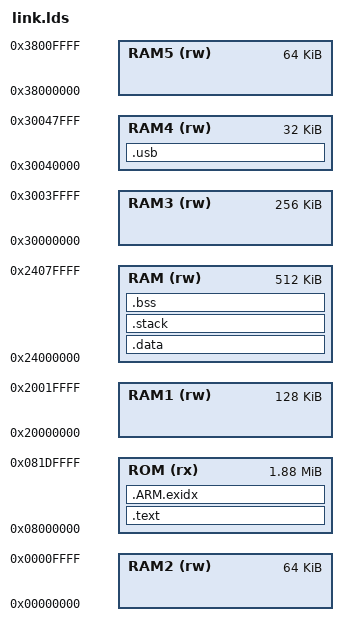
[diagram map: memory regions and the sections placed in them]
/*
 * linker script for STM32F4xx with GNU ld
 * bernard.xiong 2009-10-14
 */

/* Program Entry, set to mark it as "used" and avoid gc */
MEMORY
{
ROM  (rx) : ORIGIN =0x08000000,LENGTH =1920k
RAM  (rw) : ORIGIN =0x24000000,LENGTH =512k
RAM1 (rw) : ORIGIN =0x20000000,LENGTH =128k
RAM2 (rw) : ORIGIN =0x00000000,LENGTH =64K
RAM3 (rw) : ORIGIN =0x30000000,LENGTH =256k
RAM4 (rw) : ORIGIN =0x30040000,LENGTH =32k
RAM5 (rw) : ORIGIN =0x38000000,LENGTH =64k
}
ENTRY(Reset_Handler)
_system_stack_size = 0x200;

SECTIONS
{
    .text :
    {
        . = ALIGN(4);
        _stext = .;
        KEEP(*(.isr_vector))            /* Startup code */

        . = ALIGN(4);
        *(.text)                        /* remaining code */
        *(.text.*)                      /* remaining code */
        *(.rodata)                      /* read-only data (constants) */
        *(.rodata*)
        *(.glue_7)
        *(.glue_7t)
        *(.gnu.linkonce.t*)
        
        /* section information for finsh shell */
        . = ALIGN(4);
        __fsymtab_start = .;
        KEEP(*(FSymTab))
        __fsymtab_end = .;
        
        /* section information for usbh class */
        . = ALIGN(4);
        __usbh_class_info_start__ = .;
        KEEP(*(.usbh_class_info))
        __usbh_class_info_end__ = .;
        
        . = ALIGN(4);
        __vsymtab_start = .;
        KEEP(*(VSymTab))
        __vsymtab_end = .;
        
        /* section information for utest */
        . = ALIGN(4);
        __rt_utest_tc_tab_start = .;
        KEEP(*(UtestTcTab))
        __rt_utest_tc_tab_end = .;

        /* section information for initial. */
        . = ALIGN(4);
        __rt_init_start = .;
        KEEP(*(SORT(.rti_fn*)))
        __rt_init_end = .;
        
        /* section information for modules */
        . = ALIGN(4);
        __rtmsymtab_start = .;
        KEEP(*(RTMSymTab))
        __rtmsymtab_end = .;

        . = ALIGN(4);
        PROVIDE(__ctors_start__ = .);
        KEEP (*(SORT(.init_array.*)))
        KEEP (*(.init_array))
        PROVIDE(__ctors_end__ = .);

        . = ALIGN(4);
        _etext = .;
    } > ROM = 0

    /* .ARM.exidx is sorted, so has to go in its own output section.  */
    __exidx_start = .;
    .ARM.exidx :
    {
        *(.ARM.exidx* .gnu.linkonce.armexidx.*)

        /* This is used by the startup in order to initialize the .data secion */
        _sidata = .;
    } > ROM
    __exidx_end = .;

    /* .data section which is used for initialized data */
    .data : AT (_sidata)
    {
        . = ALIGN(4);
        /* This is used by the startup in order to initialize the .data secion */
        _sdata = . ;

        *(.data)
        *(.data.*)
        *(.gnu.linkonce.d*)

        PROVIDE(__dtors_start__ = .);
        KEEP(*(SORT(.dtors.*)))
        KEEP(*(.dtors))
        PROVIDE(__dtors_end__ = .);

        . = ALIGN(4);
        /* This is used by the startup in order to initialize the .data secion */
        _edata = . ;
    } >RAM
    
    .usb (NOLOAD):
    {
        . = ALIGN(4);
        _susb = .;

        /* section information for noncacheable */
        *(.noncacheable)     /* .data sections */
        *(.noncacheable.*)    /* .data* sections */
        *(.bss.noncacheable) /* .bss sections */
        *(.gnu.linkonce.d*)
        
        . = ALIGN(4);
        _eusb = .;
    } > RAM4

    .stack : 
    {
        . = ALIGN(4);
        _sstack = .;
        . = . + _system_stack_size;
        . = ALIGN(4);
        _estack = .;
    } >RAM

    __bss_start = .;
    .bss :
    {
        . = ALIGN(4);
        /* This is used by the startup in order to initialize the .bss secion */
        _sbss = .;

        *(.bss)
        *(.bss.*)
        *(COMMON)

        . = ALIGN(4);
        /* This is used by the startup in order to initialize the .bss secion */
        _ebss = . ;
        
        *(.bss.init)
    } > RAM
    __bss_end = .;
    _end = .;

    /* Stabs debugging sections.  */
    .stab          0 : { *(.stab) }
    .stabstr       0 : { *(.stabstr) }
    .stab.excl     0 : { *(.stab.excl) }
    .stab.exclstr  0 : { *(.stab.exclstr) }
    .stab.index    0 : { *(.stab.index) }
    .stab.indexstr 0 : { *(.stab.indexstr) }
    .comment       0 : { *(.comment) }
    /* DWARF debug sections.
     * Symbols in the DWARF debugging sections are relative to the beginning
     * of the section so we begin them at 0.  */
    /* DWARF 1 */
    .debug          0 : { *(.debug) }
    .line           0 : { *(.line) }
    /* GNU DWARF 1 extensions */
    .debug_srcinfo  0 : { *(.debug_srcinfo) }
    .debug_sfnames  0 : { *(.debug_sfnames) }
    /* DWARF 1.1 and DWARF 2 */
    .debug_aranges  0 : { *(.debug_aranges) }
    .debug_pubnames 0 : { *(.debug_pubnames) }
    /* DWARF 2 */
    .debug_info     0 : { *(.debug_info .gnu.linkonce.wi.*) }
    .debug_abbrev   0 : { *(.debug_abbrev) }
    .debug_line     0 : { *(.debug_line) }
    .debug_frame    0 : { *(.debug_frame) }
    .debug_str      0 : { *(.debug_str) }
    .debug_loc      0 : { *(.debug_loc) }
    .debug_macinfo  0 : { *(.debug_macinfo) }
    /* SGI/MIPS DWARF 2 extensions */
    .debug_weaknames 0 : { *(.debug_weaknames) }
    .debug_funcnames 0 : { *(.debug_funcnames) }
    .debug_typenames 0 : { *(.debug_typenames) }
    .debug_varnames  0 : { *(.debug_varnames) }
}
